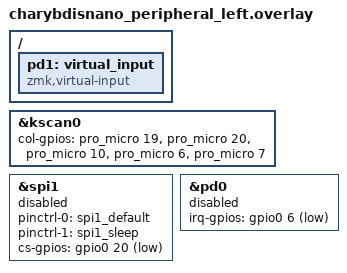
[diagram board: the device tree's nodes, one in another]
/*
 * Copyright (c) 2020 ZMK Contributors
 *
 * SPDX-License-Identifier: MIT
 */

#include "charybdisnano.dtsi"

&kscan0 {
	col-gpios
		= <&pro_micro 19 GPIO_ACTIVE_HIGH>
		, <&pro_micro 20 GPIO_ACTIVE_HIGH>
		, <&pro_micro 10 GPIO_ACTIVE_HIGH>
		, <&pro_micro 6 GPIO_ACTIVE_HIGH>
		, <&pro_micro 7 GPIO_ACTIVE_HIGH>
		;
};

#include "charybdisnano_trackball.dtsi"
/* enable &pd0 on split peripheral. typical input device for zephyr input subsystem. */
/* NOTE 1: use the same device alias (&pd0) on central and peripheral(s) is alright. */
/* NOTE 2: input event shall be intecepted by module `zmk-split-peripheral-input-relay`. */
&spi1 {
  status = "disabled";
	pinctrl-0 = <&spi1_default>;
	pinctrl-1 = <&spi1_sleep>;
	pinctrl-names = "default", "sleep";
	cs-gpios = <&gpio0 20 GPIO_ACTIVE_LOW>;
};

&pd0 {
  status = "disabled";
  irq-gpios = <&gpio0 6 (GPIO_ACTIVE_LOW | GPIO_PULL_UP)>;
};

/ {
	/* THIS make keymap binding happy only, nothing happen on peripheral side */
	pd1: virtual_input {
		compatible = "zmk,virtual-input";
	};
};

